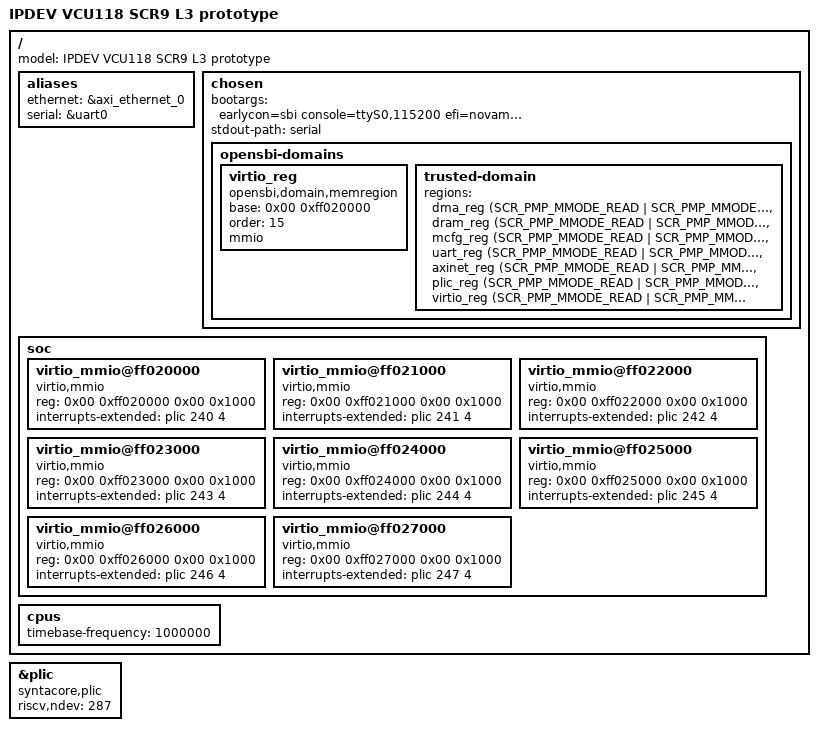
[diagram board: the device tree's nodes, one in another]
/* SPDX-License-Identifier: GPL-2.0 */
/*
 * SCR9 L3 cluster QEMU device tree.
 *
 * Same composition as the Linux vcu118_scr9_l3.dts, plus the virtio-mmio
 * transports the SC-DT QEMU machine model creates at 0xff020000..0xff027000
 * (IRQs 240..247). The Linux tree carries no such nodes because the real
 * VCU118 prototype has no virtio hardware; they describe the QEMU machine
 * only, and an opensbi-domains region is added so the trusted-domain payload
 * (and the kernel it boots) may reach the transports through the PMP.
 */

/dts-v1/;

#define SYSCLK 50000000
#define CPUCLK 80000000

#include "scr9.dtsi"
#include "vcu118_l3.dtsi"
#include "scr_qemu_cpu_isa.dtsi"

/ {
	model = "IPDEV VCU118 SCR9 L3 prototype";

	aliases {
		ethernet = &axi_ethernet_0;
		serial = &uart0;
	};

	chosen {
		bootargs = "earlycon=sbi console=ttyS0,115200 efi=novamap initrdmem=0x430000000,512M net.ifnames=0 swiotlb=noforce";
		stdout-path = "serial";

		opensbi-domains {
			virtio_reg: virtio_reg {
				compatible = "opensbi,domain,memregion";
				base = <0x00 0xff020000>;
				order = <15>; /* Exactly 32 KiB for eight transports. */
				mmio;
			};

			trusted-domain {
				regions =
					<&dma_reg (SCR_PMP_MMODE_READ | SCR_PMP_MMODE_WRITE |
						   SCR_PMP_SUMODE_READ | SCR_PMP_SUMODE_WRITE |
						   SCR_PMA_UNC)>,
					<&dram_reg (SCR_PMP_MMODE_READ | SCR_PMP_MMODE_WRITE | SCR_PMP_MMODE_EXECUTE |
						    SCR_PMP_SUMODE_READ | SCR_PMP_SUMODE_WRITE | SCR_PMP_SUMODE_EXECUTE)>,
					<&mcfg_reg (SCR_PMP_MMODE_READ | SCR_PMP_MMODE_WRITE |
						    SCR_PMP_SUMODE_READ |
						    SCR_PMA_MMIO)>,
					<&uart_reg (SCR_PMP_MMODE_READ | SCR_PMP_MMODE_WRITE |
						    SCR_PMP_SUMODE_READ | SCR_PMP_SUMODE_WRITE |
						    SCR_PMA_UNC)>,
					<&axinet_reg (SCR_PMP_MMODE_READ | SCR_PMP_MMODE_WRITE |
						      SCR_PMP_SUMODE_READ | SCR_PMP_SUMODE_WRITE |
						      SCR_PMA_UNC)>,
					<&plic_reg (SCR_PMP_MMODE_READ | SCR_PMP_MMODE_WRITE |
						    SCR_PMP_SUMODE_READ | SCR_PMP_SUMODE_WRITE |
						    SCR_PMA_UNC)>,
					<&virtio_reg (SCR_PMP_MMODE_READ | SCR_PMP_MMODE_WRITE |
						      SCR_PMP_SUMODE_READ | SCR_PMP_SUMODE_WRITE |
						      SCR_PMA_MMIO)>;
				/* The regions list above replaces the one from
				 * vcu118_l3.dtsi wholesale: it is the original six
				 * entries plus virtio_reg. */
			};
		};
	};

	soc {
		virtio_mmio@ff020000 {
			compatible = "virtio,mmio";
			reg = <0x00 0xff020000 0x00 0x1000>;
			interrupts-extended = <&plic 240 4>;
		};

		virtio_mmio@ff021000 {
			compatible = "virtio,mmio";
			reg = <0x00 0xff021000 0x00 0x1000>;
			interrupts-extended = <&plic 241 4>;
		};

		virtio_mmio@ff022000 {
			compatible = "virtio,mmio";
			reg = <0x00 0xff022000 0x00 0x1000>;
			interrupts-extended = <&plic 242 4>;
		};

		virtio_mmio@ff023000 {
			compatible = "virtio,mmio";
			reg = <0x00 0xff023000 0x00 0x1000>;
			interrupts-extended = <&plic 243 4>;
		};

		virtio_mmio@ff024000 {
			compatible = "virtio,mmio";
			reg = <0x00 0xff024000 0x00 0x1000>;
			interrupts-extended = <&plic 244 4>;
		};

		virtio_mmio@ff025000 {
			compatible = "virtio,mmio";
			reg = <0x00 0xff025000 0x00 0x1000>;
			interrupts-extended = <&plic 245 4>;
		};

		virtio_mmio@ff026000 {
			compatible = "virtio,mmio";
			reg = <0x00 0xff026000 0x00 0x1000>;
			interrupts-extended = <&plic 246 4>;
		};

		virtio_mmio@ff027000 {
			compatible = "virtio,mmio";
			reg = <0x00 0xff027000 0x00 0x1000>;
			interrupts-extended = <&plic 247 4>;
		};
	};

	cpus {
		timebase-frequency = <1000000>;
	};
};

/* Stock kernels bind the sifive-plic driver, not "syntacore,plic";
 * add the standard compatible so virtio and the UART get their IRQs. */
&plic {
	compatible = "syntacore,plic", "sifive,plic-1.0.0";
	/* QEMU provides 288 sources, including reserved source zero. */
	riscv,ndev = <287>;
};

SCR_QEMU_CPU_ZICBOM_OVERRIDES(8)
